VERSION "HIPBNYYYYYYYYYYYYYYYYYYYYYYYYYYYYYYYYYYYYY/4/%%%/4/'%**4YYY///"

NS_ :

BS_:

BU_:

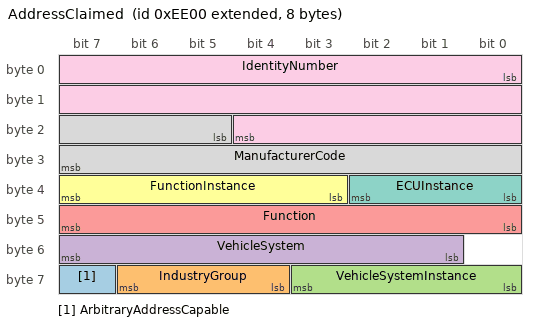
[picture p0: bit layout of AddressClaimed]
BO_ 2147544576 AddressClaimed: 8 Vector__XXX
 SG_ ArbitraryAddressCapable : 63|1@1+ (1,0) [0|0] "" Vector__XXX
 SG_ IndustryGroup : 60|3@1+ (1,0) [0|0] "" Vector__XXX
 SG_ VehicleSystemInstance : 56|4@1+ (1,0) [0|0] "" Vector__XXX
 SG_ VehicleSystem : 49|7@1+ (1,0) [0|0] "" Vector__XXX
 SG_ Function : 40|8@1+ (1,0) [0|0] "" Vector__XXX
 SG_ FunctionInstance : 35|5@1+ (1,0) [0|0] "" Vector__XXX
 SG_ ECUInstance : 32|3@1+ (1,0) [0|0] "" Vector__XXX
 SG_ ManufacturerCode : 21|11@1+ (1,0) [0|0] "" Vector__XXX
 SG_ IdentityNumber : 0|21@1+ (1,0) [0|0] "" Vector__XXX
